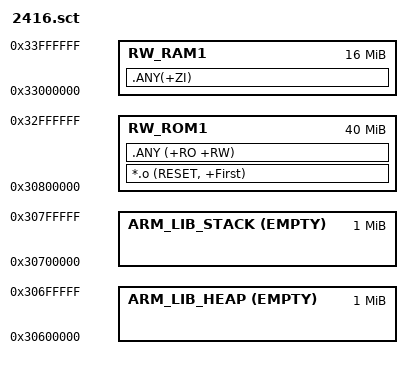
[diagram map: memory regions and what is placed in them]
; *************************************************************
; *** Scatter-Loading Description File generated by uVision ***
; *************************************************************

LR_ROM1 0x30800000 0x2800000 {    		; load region size_region
	RW_ROM1 0x30800000 0x2800000  {  	; load address = execution address
		*.o (RESET, +First)
		.ANY (+RO +RW)
  
	}
	RW_RAM1 0x33000000 0x1000000  {  
		.ANY(+ZI)
	}
  
	ARM_LIB_HEAP  0x30600000 EMPTY  0x00100000 {
		
	}
	ARM_LIB_STACK 0x30800000 EMPTY -0x00100000 {
		
	}
	
}

